# AS32x601 register map
File version: 1.0
CPU: RISC-V, little endian
Registers are 32-bit, read-write, reset 0x0 unless marked. A register's access mark holds for its fields unless they carry their own. Offsets are from the block's base; [hi:lo] are bit positions; lines under a group give offsets from that group; {n}, {i} and the like mark numbered series.

## ADC0 — Analog-to-Digital Converter 0
Base 0x41001000
Same registers: ADC1 0x41002000
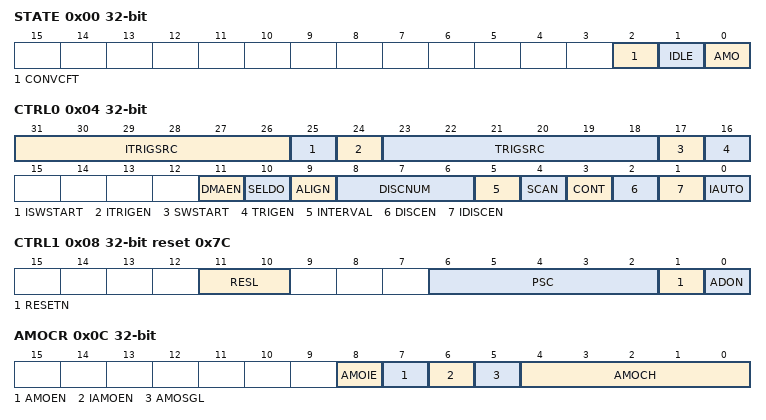
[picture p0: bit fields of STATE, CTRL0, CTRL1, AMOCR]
0x00 STATE — ADC Status Register
  [2] CONVCFT — Convert trigger conflict status
  [1] IDLE — ADC idle state flag
  [0] AMO — Analog monitor event occurs
0x04 CTRL0 — ADC Control Register 0
  [31:26] ITRIGSRC — Injection group trigger source select
  [25] ISWSTART — Software trigger for injection channels
  [24] ITRIGEN — Injection group trigger enable
  [23:18] TRIGSRC — Regular group trigger source select
  [17] SWSTART — Software trigger for regular channels
  [16] TRIGEN — Regular group trigger enable
  [11] DMAEN — DMA function enable
  [10] SELDO — Data type selection
  [9] ALIGN — Data alignment
  [8:6] DISCNUM — Discontinuous conversion length of channel
  [5] INTERVAL — Interval mode
  [4] SCAN — ADC SCAN operation mode
  [3] CONT — ADC CONT operation mode
  [2] DISCEN — ADC DISCEN operation mode
  [1] IDISCEN — ADC IDISCEN operation mode
  [0] IAUTO — ADC IAUTO operation mode
0x08 CTRL1 reset 0x7C — ADC Control Register 1
  [11:10] RESL — ADC conversion resolution selection
  [6:2] PSC — ADC conversion clock prescaler used to generate ADCCLK
  [1] RESETN — ADC reset
  [0] ADON — ADC Power on
0x0C AMOCR — ADC Analog monitor Configure Register
  [8] AMOIE — AMO interrupt function enable
  [7] AMOEN — Analog monitor AMOEN function configuration
  [6] IAMOEN — Analog monitor IAMOEN function configuration
  [5] AMOSGL — Analog monitor AMOSGL function configuration
  [4:0] AMOCH — Analog monitor detecting channel
0x10 AMOHR — ADC AMO High Threshold Register
  [11:0] AMOHT — Analog monitor higher threshold
0x14 AMOLR — ADC AMO Low Threshold Register
  [11:0] AMOLT — Analog monitor lower threshold
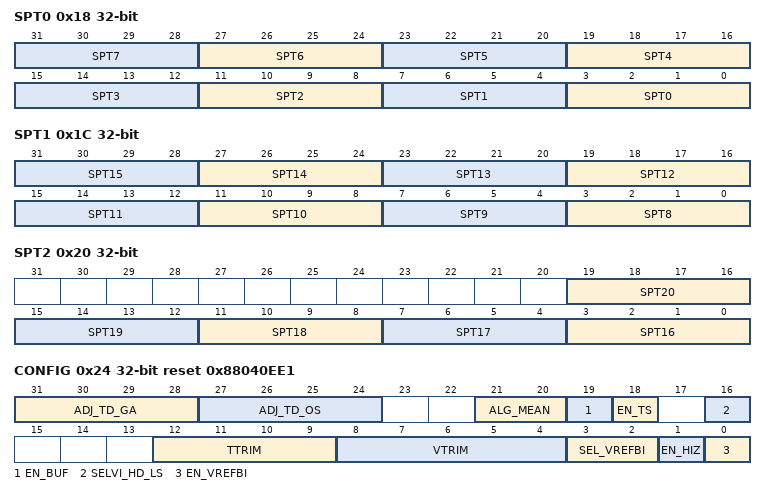
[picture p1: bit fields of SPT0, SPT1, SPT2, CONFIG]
0x18 SPT0 — ADC Sample Time Selection Register 0
  [4n+3:4n] SPT{n} (n=0..7) — Sample time selection for channel {n}
0x1C SPT1 — ADC Sample Time Selection Register 1
  [4n-29:4n-32] SPT{n} (n=8..15) — Sample time selection for channel {n}
0x20 SPT2 — ADC Sample Time Selection Register 2
  [4n-61:4n-64] SPT{n} (n=16..20) — Sample time selection for channel {n}
0x24 CONFIG reset 0x88040EE1 — ADC Configure Register
  [31:28] ADJ_TD_GA — Temperature sensor gain adjustment signal
  [27:24] ADJ_TD_OS — Temperature sensor offset adjustment signal
  [21:20] ALG_MEAN — Temperature sampling points selection for mean algorithm
  [19] EN_BUF — Detected external reference input buffer enable signal
  [18] EN_TS — Temperature sensor enable signal
  [16] SELVI_HD_LS — SAR input type selection
  [12:9] TTRIM — Built-In reference voltage temperature ratio control
  [8:4] VTRIM — Built-In reference voltage output control
  [3:2] SEL_VREFBI — Built-in reference output voltage selected signal
  [1] EN_HIZ — High-resistance state control signal
  [0] EN_VREFBI — Built-in reference voltage enable signal
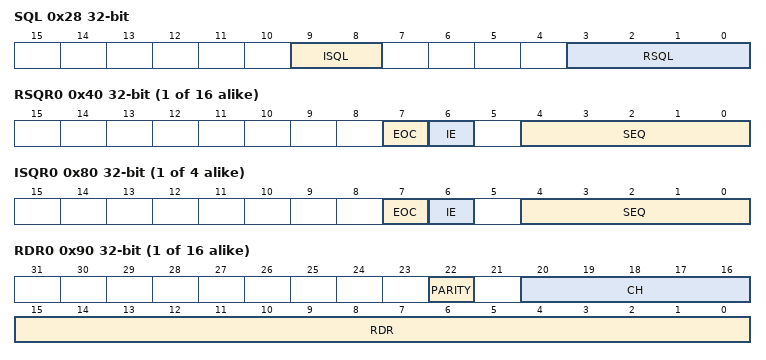
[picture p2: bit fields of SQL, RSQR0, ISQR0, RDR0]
0x28 SQL — ADC Regular Sequence Length Register
  [9:8] ISQL — Length of the injection group
  [3:0] RSQL — Length of the regular group
{0x30+4i} IOFR{i} (i=0..3) — ADC Injection Group Offset Register {i}
  [11:0] IOFR — Injection group offset value
{0x40+4i} RSQR{i} (i=0..15) — ADC Regular Group Sequence Configure Register {i}
  [7] EOC — Indicate Regular Sequence conversion end
  [6] IE — EOC interrupt enable
  [4:0] SEQ — Channel selection for regular group
{0x80+4i} ISQR{i} (i=0..3) — ADC Injection Group Sequence Configure Register {i}
  [7] EOC — Indicate Regular Sequence conversion end
  [6] IE — EOC interrupt enable
  [4:0] SEQ — Channel selection for injection group
{0x90+4i} RDR{i} ro (i=0..15) — ADC Regular Group Data Register {i}
  [22] PARITY — Parity for regular conversion data
  [20:16] CH — Channel selection for regular group
  [15:0] RDR — Data register for regular group
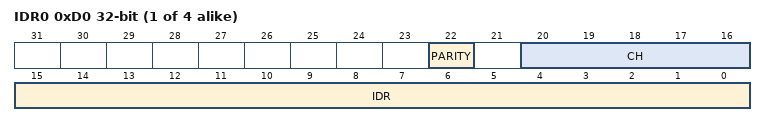
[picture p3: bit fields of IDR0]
{0xD0+4i} IDR{i} ro (i=0..3) — ADC Injection Group Data Register {i}
  [22] PARITY — Parity for injection conversion data
  [20:16] CH — Channel selection for injection group
  [15:0] IDR — Data register for injection group
